VERSION ""

NS_ :

BS_:

BU_: Vector__XXX

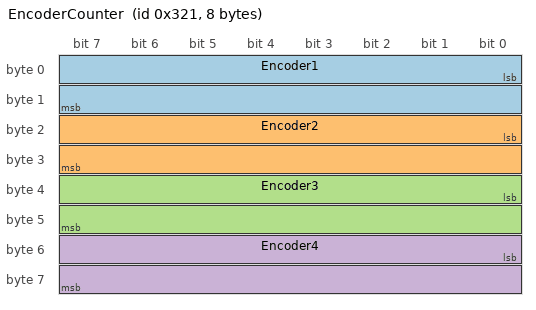
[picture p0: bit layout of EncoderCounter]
BO_ 801 EncoderCounter: 8 Vector__XXX
SG_ Encoder1 : 0|16@1+ (1,0) [0|65535] "" Vector__XXX
SG_ Encoder2 : 16|16@1+ (1,0) [0|65535] "" Vector__XXX
SG_ Encoder3 : 32|16@1+ (1,0) [0|65535] "" Vector__XXX
SG_ Encoder4 : 48|16@1+ (1,0) [0|65535] "" Vector__XXX

CM_ BO_ 801 "Counter ENC1";

BA_DEF_  "BusType" STRING ;

BA_DEF_DEF_  "BusType" "CAN";
